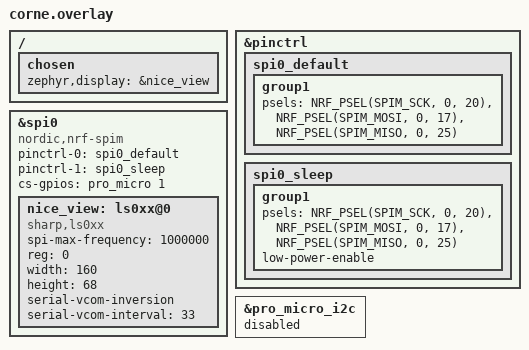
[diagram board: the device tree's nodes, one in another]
&pinctrl {
    spi0_default: spi0_default {
        group1 {
            psels = <NRF_PSEL(SPIM_SCK, 0, 20)>,
                <NRF_PSEL(SPIM_MOSI, 0, 17)>,
                <NRF_PSEL(SPIM_MISO, 0, 25)>;
        };
    };

    spi0_sleep: spi0_sleep {
        group1 {
            psels = <NRF_PSEL(SPIM_SCK, 0, 20)>,
                <NRF_PSEL(SPIM_MOSI, 0, 17)>,
                <NRF_PSEL(SPIM_MISO, 0, 25)>;
            low-power-enable;
        };
    };
};

&spi0 {
    compatible = "nordic,nrf-spim";
    status = "okay";
    pinctrl-0 = <&spi0_default>;
    pinctrl-1 = <&spi0_sleep>;
    pinctrl-names = "default", "sleep";
    cs-gpios = <&pro_micro 1 GPIO_ACTIVE_HIGH>;

    nice_view: ls0xx@0 {
        compatible = "sharp,ls0xx";
        spi-max-frequency = <1000000>;
        reg = <0>;
        width = <160>;
        height = <68>;
        serial-vcom-inversion;
        serial-vcom-interval = <33>;
    };
};

&pro_micro_i2c {
    status = "disabled";
};

/ {
    chosen {
        zephyr,display = &nice_view;
    };
};
